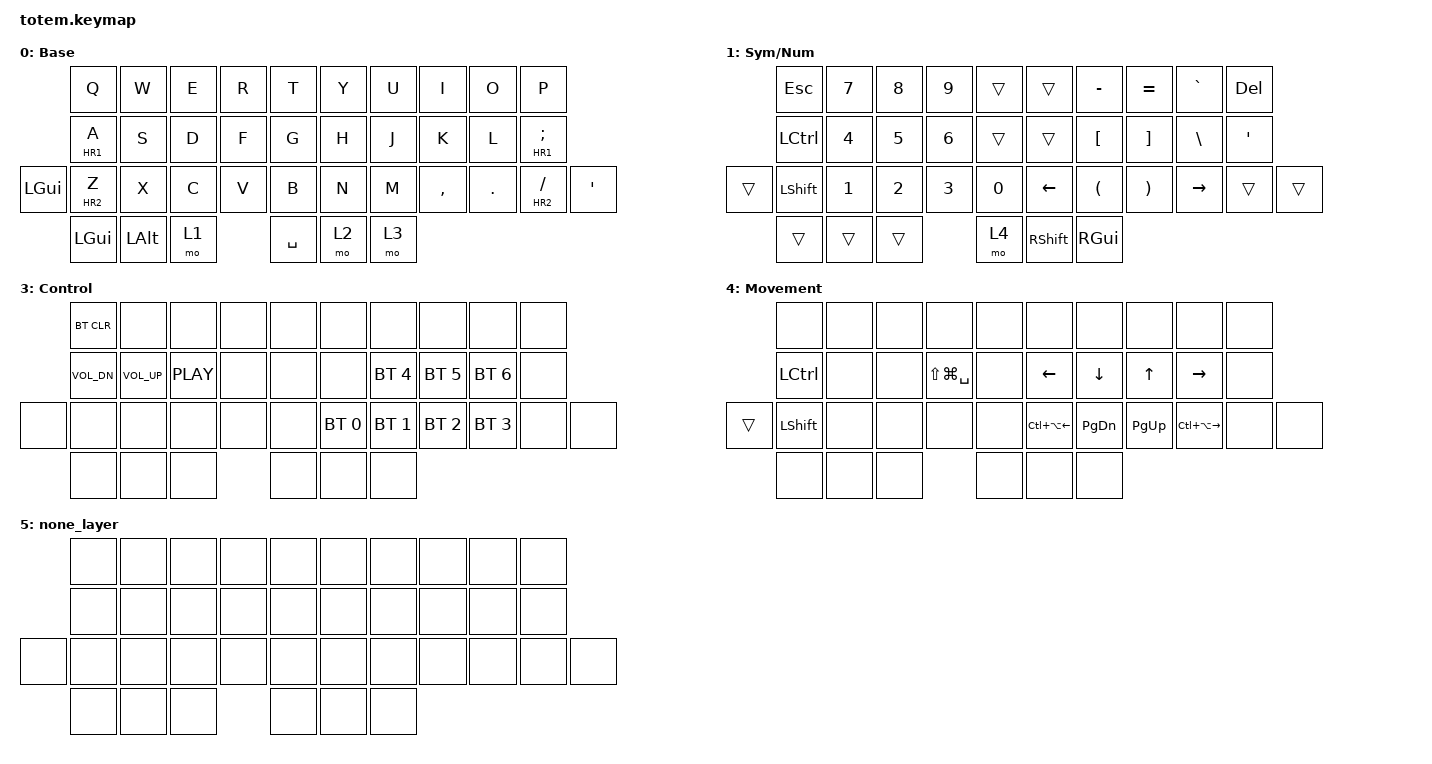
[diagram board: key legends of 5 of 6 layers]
//
//                                                        ▀▀▀▀▀     ▀▀▀▀▀          ▀▀█▀▀
//                                                        ▄▀▀▀▄  ▄  ▄▀▀▀▄  ▄  ▄▀▀▀▄  █  ▄▀▀▀▄
//                                                        █   █  █  █   █  █  █   █  █  █   █
//                                                         ▀▀▀   █   ▀▀▀   █   ▀▀▀   ▀   ▀▀▀
//                                                               █      ▄▄▄█▄▄▄    █   █  
//                                                               ▀      █  █  █     █▄█
//                                                             ▀▀▀▀▀    █  █  █      ▀
//                                                                      ▀  ▀  ▀
//
// ▄▄▄▄▄▄▄▄▄▄▄▄▄▄▄▄▄▄▄▄▄▄▄▄▄▄▄▄▄▄▄▄▄▄▄▄▄▄▄▄▄▄▄▄▄▄▄▄▄▄▄▄▄▄▄▄▄▄▄▄▄▄▄▄▄▄▄▄▄▄▄▄▄▄▄▄▄▄▄▄▄▄▄▄▄▄▄▄▄▄▄▄▄▄▄▄▄▄▄▄▄▄▄▄▄▄▄▄▄▄▄▄▄▄▄▄▄▄▄▄▄▄▄▄▄▄▄▄▄▄▄▄▄▄▄▄▄▄▄▄▄▄▄▄▄▄▄▄▄
       

#include <behaviors.dtsi>
#include <dt-bindings/zmk/keys.h>
#include <dt-bindings/zmk/bt.h>
#include <dt-bindings/zmk/outputs.h>

#define BASE 0
#define NAV  1
#define SYM  2
#define ADJ  3
#define TVP1 4
#define TVP2 5

// home row
#define HR1 LCTRL
#define HR2 LSHFT
#define HR3 RALT
#define HR4 LCTRL

#define MV_TB_L LC(LS(PG_UP))
#define MV_TB_R LC(LS(PG_DN))
#define PREV_TAB LC(LS(TAB))
#define NEXT_TAB LC(TAB)

#define PREV_SPACE LA(P)
#define NEXT_SPACE LA(N)

&lt {
    flavor = "hold-preferred";
};

&mt {
  flavor = "tap-preferred";
};

/ {
    combos {
        compatible = "zmk,combos";
        combo_esc {
            timeout-ms = <30>;
            key-positions = <1 2>;
            bindings = <&kp ESC>;
        };
        combo_tab {
            timeout-ms = <30>;
            key-positions = <11 12>;
            bindings = <&kp TAB>;
        };
        combo_bksp {
            timeout-ms = <30>;
            key-positions = <7 8>;
            bindings = <&kp BKSP>;
        };
        combo_enter {
            timeout-ms = <30>;
            key-positions = <17 18>;
            bindings = <&kp ENTER>;
        };
    };

        keymap {
                compatible = "zmk,keymap";
// ▄▄▄▄▄▄▄▄▄▄▄▄▄▄▄▄▄▄▄▄▄▄▄▄▄▄▄▄▄▄▄▄▄▄▄▄▄▄▄▄▄▄▄▄▄▄▄▄▄▄▄▄▄▄▄▄▄▄▄▄▄▄▄▄▄▄▄▄▄▄▄▄▄▄▄▄▄▄▄▄▄▄▄▄▄▄▄▄▄▄▄▄▄▄▄▄▄▄▄▄▄▄▄▄▄▄▄▄▄▄▄▄▄▄▄▄▄▄▄▄▄▄▄▄▄▄▄▄▄▄▄▄▄▄▄▄▄▄▄▄▄▄▄▄▄▄▄▄▄

                base_layer {
// ┏━━━━━━━━━━━━━━━━━━━━━━━━━━━━━━━━━━━━━━━┓
label= "Base"                              ;
// ┗━━━━━━━━━━━━━━━━━━━━━━━━━━━━━━━━━━━━━━━┛
//             ┏━━━━━━━━━━━┳━━━━━━━━━━━┳━━━━━━━━━━━┳━━━━━━━━━━━┳━━━━━━━━━━━┓   ┏━━━━━━━━━━━┳━━━━━━━━━━━┳━━━━━━━━━━━┳━━━━━━━━━━━┳━━━━━━━━━━━┓
//             ┃     Q     ┃     W     ┃     F     ┃     P     ┃     G     ┃   ┃     J     ┃     L     ┃     U     ┃     Y     ┃     ;     ┃
//             ┣━━━━━━━━━━━╋━━━━━━━━━━━╋━━━━━━━━━━━╋━━━━━━━━━━━╋━━━━━━━━━━━┫   ┣━━━━━━━━━━━╋━━━━━━━━━━━╋━━━━━━━━━━━╋━━━━━━━━━━━╋━━━━━━━━━━━┫
//             ┃     A     ┃     R     ┃     S     ┃     T     ┃     D     ┃   ┃     H     ┃     N     ┃     E     ┃     I     ┃     O     ┃
// ┏━━━━━━━━━━━╋━━━━━━━━━━━╋━━━━━━━━━━━╋━━━━━━━━━━━╋━━━━━━━━━━━╋━━━━━━━━━━━┫   ┣━━━━━━━━━━━╋━━━━━━━━━━━╋━━━━━━━━━━━╋━━━━━━━━━━━╋━━━━━━━━━━━╋━━━━━━━━━━━┓
// ┃     Q     ┃     Z     ┃     X     ┃     C     ┃     V     ┃     B     ┃   ┃     K     ┃     M     ┃     ,     ┃     .     ┃     /     ┃     \     ┃
// ┗━━━━━━━━━━━┻━━━━━━━━━━━┻━━━━━━━━━━━╋━━━━━━━━━━━╋━━━━━━━━━━━╋━━━━━━━━━━━┫   ┣━━━━━━━━━━━╋━━━━━━━━━━━╋━━━━━━━━━━━╋━━━━━━━━━━━┻━━━━━━━━━━━┻━━━━━━━━━━━┛
//                                     ┃    DEL    ┃    TAB    ┃    SPC    ┃   ┃   ENTER   ┃           ┃   BSPC    ┃
//                                     ┗━━━━━━━━━━━┻━━━━━━━━━━━┻━━━━━━━━━━━┛   ┗━━━━━━━━━━━┻━━━━━━━━━━━┻━━━━━━━━━━━┛
        bindings = <
            &kp Q &kp      W &kp      E &kp      R &kp T          &kp Y &kp      U &kp      I &kp      O &kp P
            &mt HR1 A &kp  S &kp      D &kp      F &kp G          &kp H &kp      J &kp      K &kp      L &mt HR1 SEMI 
&kp LGUI    &mt HR2 Z &kp  X &kp      C &kp      V &kp B          &kp N &kp      M &kp  COMMA &kp    DOT &mt HR2 FSLH &kp SQT
                 &kp LGUI  &kp LALT   &mo 1           &kp SPACE  &mo 2   &mo 3 
            >;
                };

// ▄▄▄▄▄▄▄▄▄▄▄▄▄▄▄▄▄▄▄▄▄▄▄▄▄▄▄▄▄▄▄▄▄▄▄▄▄▄▄▄▄▄▄▄▄▄▄▄▄▄▄▄▄▄▄▄▄▄▄▄▄▄▄▄▄▄▄▄▄▄▄▄▄▄▄▄▄▄▄▄▄▄▄▄▄▄▄▄▄▄▄▄▄▄▄▄▄▄▄▄▄▄▄▄▄▄▄▄▄▄▄▄▄▄▄▄▄▄▄▄▄▄▄▄▄▄▄▄▄▄▄▄▄▄▄▄▄▄▄▄▄▄▄▄▄▄▄▄▄


                lower_layer {
// ┏━━━━━━━━━━━━━━━━━━━━━━━━━━━━━━━━━━━━━━━┓
label= "Sym/Num"                              ;
// ┗━━━━━━━━━━━━━━━━━━━━━━━━━━━━━━━━━━━━━━━┛
//             ┏━━━━━━━━━━━┳━━━━━━━━━━━┳━━━━━━━━━━━┳━━━━━━━━━━━┳━━━━━━━━━━━┓   ┏━━━━━━━━━━━┳━━━━━━━━━━━┳━━━━━━━━━━━┳━━━━━━━━━━━┳━━━━━━━━━━━┓
//             ┃           ┃           ┃     UP    ┃           ┃     {     ┃   ┃     }     ┃     7     ┃     8     ┃     9     ┃     +     ┃
//             ┣━━━━━━━━━━━╋━━━━━━━━━━━╋━━━━━━━━━━━╋━━━━━━━━━━━╋━━━━━━━━━━━┫   ┣━━━━━━━━━━━╋━━━━━━━━━━━╋━━━━━━━━━━━╋━━━━━━━━━━━╋━━━━━━━━━━━┫
//             ┃   SHIFT   ┃   LEFT    ┃    DOWN   ┃   RIGHT   ┃     [     ┃   ┃     ]     ┃     4     ┃     5     ┃     6     ┃     -     ┃
// ┏━━━━━━━━━━━╋━━━━━━━━━━━╋━━━━━━━━━━━╋━━━━━━━━━━━╋━━━━━━━━━━━╋━━━━━━━━━━━┫   ┣━━━━━━━━━━━╋━━━━━━━━━━━╋━━━━━━━━━━━╋━━━━━━━━━━━╋━━━━━━━━━━━╋━━━━━━━━━━━┓
// ┃           ┃           ┃   P UP    ┃  C LOCK   ┃  P DOWN   ┃     (     ┃   ┃     )     ┃     1     ┃     2     ┃     3     ┃     *     ┃           ┃
// ┗━━━━━━━━━━━┻━━━━━━━━━━━┻━━━━━━━━━━━╋━━━━━━━━━━━╋━━━━━━━━━━━╋━━━━━━━━━━━┫   ┣━━━━━━━━━━━╋━━━━━━━━━━━╋━━━━━━━━━━━╋━━━━━━━━━━━┻━━━━━━━━━━━┻━━━━━━━━━━━┛
//                                     ┃           ┃    TAB    ┃    SPC    ┃   ┃    DEL    ┃     0     ┃           ┃
//                                     ┗━━━━━━━━━━━┻━━━━━━━━━━━┻━━━━━━━━━━━┛   ┗━━━━━━━━━━━┻━━━━━━━━━━━┻━━━━━━━━━━━┛
        bindings = <
                &kp ESC   &kp N7 &kp N8 &kp N9 &trans   &trans &kp MINUS &kp EQUAL  &kp GRAVE  &kp DEL
                &kp LCTRL &kp N4 &kp N5 &kp N6 &trans   &trans &kp LBKT  &kp RBKT   &kp BSLH   &kp SQT
     &trans     &kp LSHFT &kp N1 &kp N2 &kp N3 &kp N0   &kp LEFT &kp LPAR  &kp RPAR   &kp RIGHT     &trans &trans
                &trans &trans &trans   &mo 4 &kp RSHFT &kp RGUI
                >;
                };

// ▄▄▄▄▄▄▄▄▄▄▄▄▄▄▄▄▄▄▄▄▄▄▄▄▄▄▄▄▄▄▄▄▄▄▄▄▄▄▄▄▄▄▄▄▄▄▄▄▄▄▄▄▄▄▄▄▄▄▄▄▄▄▄▄▄▄▄▄▄▄▄▄▄▄▄▄▄▄▄▄▄▄▄▄▄▄▄▄▄▄▄▄▄▄▄▄▄▄▄▄▄▄▄▄▄▄▄▄▄▄▄▄▄▄▄▄▄▄▄▄▄▄▄▄▄▄▄▄▄▄▄▄▄▄▄▄▄▄▄▄▄▄▄▄▄▄▄▄▄


                nav_layer {
// ┏━━━━━━━━━━━━━━━━━━━━━━━━━━━━━━━━━━━━━━━┓
label= "Nav"                               ;
// ┗━━━━━━━━━━━━━━━━━━━━━━━━━━━━━━━━━━━━━━━┛
//             ┏━━━━━━━━━━━┳━━━━━━━━━━━┳━━━━━━━━━━━┳━━━━━━━━━━━┳━━━━━━━━━━━┓   ┏━━━━━━━━━━━┳━━━━━━━━━━━┳━━━━━━━━━━━┳━━━━━━━━━━━┳━━━━━━━━━━━┓
//             ┃     !     ┃     @     ┃     #     ┃     $     ┃     %     ┃   ┃     ˆ     ┃     &     ┃     Ü     ┃     '     ┃     "     ┃
//             ┣━━━━━━━━━━━╋━━━━━━━━━━━╋━━━━━━━━━━━╋━━━━━━━━━━━╋━━━━━━━━━━━┫   ┣━━━━━━━━━━━╋━━━━━━━━━━━╋━━━━━━━━━━━╋━━━━━━━━━━━╋━━━━━━━━━━━┫
//             ┃     Ä     ┃           ┃    SZ     ┃           ┃           ┃   ┃   MUTE    ┃   YEN     ┃   EURO    ┃  POUND    ┃     Ö     ┃
// ┏━━━━━━━━━━━╋━━━━━━━━━━━╋━━━━━━━━━━━╋━━━━━━━━━━━╋━━━━━━━━━━━╋━━━━━━━━━━━┫   ┣━━━━━━━━━━━╋━━━━━━━━━━━╋━━━━━━━━━━━╋━━━━━━━━━━━╋━━━━━━━━━━━╋━━━━━━━━━━━┓
// ┃           ┃  EMAIL1   ┃  EMAIL2   ┃           ┃           ┃           ┃   ┃   VOL-    ┃   VOL+    ┃   LAST    ┃   NEXT    ┃     \     ┃           ┃
// ┗━━━━━━━━━━━┻━━━━━━━━━━━┻━━━━━━━━━━━╋━━━━━━━━━━━╋━━━━━━━━━━━╋━━━━━━━━━━━┫   ┣━━━━━━━━━━━╋━━━━━━━━━━━╋━━━━━━━━━━━╋━━━━━━━━━━━┻━━━━━━━━━━━┻━━━━━━━━━━━┛
//                                     ┃           ┃    GIF    ┃    ADJ    ┃   ┃           ┃           ┃           ┃
//                                     ┗━━━━━━━━━━━┻━━━━━━━━━━━┻━━━━━━━━━━━┛   ┗━━━━━━━━━━━┻━━━━━━━━━━━┻━━━━━━━━━━━┛
        bindings = <
                &kp LG(N1)    &kp LG(N2)   &kp LG(N3) &kp LG(N4)   &kp LG(N5)         &kp LG(N6)    &kp LG(N7)   &kp LG(N8) &kp LG(N9)  &trans 
                &kp LCTRL     &kp LA(N4)   &kp LA(N5) &kp LA(N6)   &trans             &kp MV_TB_L &kp PREV_TAB &kp NEXT_TAB &kp MV_TB_R &kp BSLH
       &trans   &kp LSHFT     &kp LA(N1)   &kp LA(N2) &kp LA(N3)   &trans             &kp LS(LA(P)) &kp LA(P)  &kp LA(N) &kp LS(LA(N))  &trans
                &trans &trans &trans   &trans &trans &trans
                >;
        };

// ▄▄▄▄▄▄▄▄▄▄▄▄▄▄▄▄▄▄▄▄▄▄▄▄▄▄▄▄▄▄▄▄▄▄▄▄▄▄▄▄▄▄▄▄▄▄▄▄▄▄▄▄▄▄▄▄▄▄▄▄▄▄▄▄▄▄▄▄▄▄▄▄▄▄▄▄▄▄▄▄▄▄▄▄▄▄▄▄▄▄▄▄▄▄▄▄▄▄▄▄▄▄▄▄▄▄▄▄▄▄▄▄▄▄▄▄▄▄▄▄▄▄▄▄▄▄▄▄▄▄▄▄▄▄▄▄▄▄▄▄▄▄▄▄▄▄▄▄▄


                control_layer {
// ┏━━━━━━━━━━━━━━━━━━━━━━━━━━━━━━━━━━━━━━━┓
label= "Control"                               ;
// ┗━━━━━━━━━━━━━━━━━━━━━━━━━━━━━━━━━━━━━━━┛
//             ┏━━━━━━━━━━━┳━━━━━━━━━━━┳━━━━━━━━━━━┳━━━━━━━━━━━┳━━━━━━━━━━━┓   ┏━━━━━━━━━━━┳━━━━━━━━━━━┳━━━━━━━━━━━┳━━━━━━━━━━━┳━━━━━━━━━━━┓
//             ┃   RESET   ┃ BT CLEAR  ┃  OUT TOG  ┃           ┃           ┃   ┃           ┃    F7     ┃    F8     ┃    F9     ┃    F12    ┃
//             ┣━━━━━━━━━━━╋━━━━━━━━━━━╋━━━━━━━━━━━╋━━━━━━━━━━━╋━━━━━━━━━━━┫   ┣━━━━━━━━━━━╋━━━━━━━━━━━╋━━━━━━━━━━━╋━━━━━━━━━━━╋━━━━━━━━━━━┫
//             ┃ BOOTLOAD  ┃ BT NEXT   ┃           ┃           ┃           ┃   ┃           ┃    F4     ┃    F5     ┃    F6     ┃    F11    ┃
// ┏━━━━━━━━━━━╋━━━━━━━━━━━╋━━━━━━━━━━━╋━━━━━━━━━━━╋━━━━━━━━━━━╋━━━━━━━━━━━┫   ┣━━━━━━━━━━━╋━━━━━━━━━━━╋━━━━━━━━━━━╋━━━━━━━━━━━╋━━━━━━━━━━━╋━━━━━━━━━━━┓
// ┃           ┃           ┃ BT PREV   ┃           ┃           ┃           ┃   ┃           ┃    F1     ┃    F2     ┃    F3     ┃    F10    ┃           ┃
// ┗━━━━━━━━━━━┻━━━━━━━━━━━┻━━━━━━━━━━━╋━━━━━━━━━━━╋━━━━━━━━━━━╋━━━━━━━━━━━┫   ┣━━━━━━━━━━━╋━━━━━━━━━━━╋━━━━━━━━━━━╋━━━━━━━━━━━┻━━━━━━━━━━━┻━━━━━━━━━━━┛
//                                     ┃           ┃           ┃           ┃   ┃           ┃           ┃           ┃
//                                     ┗━━━━━━━━━━━┻━━━━━━━━━━━┻━━━━━━━━━━━┛   ┗━━━━━━━━━━━┻━━━━━━━━━━━┻━━━━━━━━━━━┛
            bindings = <
&bt BT_CLR   &none        &none      &none &none    &none &none &none &none &none
&kp C_VOL_DN &kp C_VOL_UP &kp C_PLAY &none &none    &none &bt BT_SEL 4 &bt BT_SEL 5 &bt BT_SEL 6 &none
&none &none &none &none &none &none                       &bt BT_SEL 0 &bt BT_SEL 1 &bt BT_SEL 2 &bt BT_SEL 3 &none &none
            &none &none &none                       &none &none &none
            >;
                };

// ▄▄▄▄▄▄▄▄▄▄▄▄▄▄▄▄▄▄▄▄▄▄▄▄▄▄▄▄▄▄▄▄▄▄▄▄▄▄▄▄▄▄▄▄▄▄▄▄▄▄▄▄▄▄▄▄▄▄▄▄▄▄▄▄▄▄▄▄▄▄▄▄▄▄▄▄▄▄▄▄▄▄▄▄▄▄▄▄▄▄▄▄▄▄▄▄▄▄▄▄▄▄▄▄▄▄▄▄▄▄▄▄▄▄▄▄▄▄▄▄▄▄▄▄▄▄▄▄▄▄▄▄▄▄▄▄▄▄▄▄▄▄▄▄▄▄▄▄▄


                movement_layer {
// ┏━━━━━━━━━━━━━━━━━━━━━━━━━━━━━━━━━━━━━━━┓
label= "Movement"                             ;
// ┗━━━━━━━━━━━━━━━━━━━━━━━━━━━━━━━━━━━━━━━┛
//             ┏━━━━━━━━━━━┳━━━━━━━━━━━┳━━━━━━━━━━━┳━━━━━━━━━━━┳━━━━━━━━━━━┓   ┏━━━━━━━━━━━┳━━━━━━━━━━━┳━━━━━━━━━━━┳━━━━━━━━━━━┳━━━━━━━━━━━┓
//             ┃ NEXT FILE ┃ MARK IN   ┃ ROTATE    ┃ MARK OUT  ┃ SHOW SNAP ┃   ┃           ┃           ┃           ┃           ┃           ┃
//             ┣━━━━━━━━━━━╋━━━━━━━━━━━╋━━━━━━━━━━━╋━━━━━━━━━━━╋━━━━━━━━━━━┫   ┣━━━━━━━━━━━╋━━━━━━━━━━━╋━━━━━━━━━━━╋━━━━━━━━━━━╋━━━━━━━━━━━┫
//             ┃ TVP II    ┃ LEFT      ┃ PAN       ┃ RIGHT     ┃ PLAY/FLIP ┃   ┃           ┃           ┃           ┃           ┃           ┃
// ┏━━━━━━━━━━━╋━━━━━━━━━━━╋━━━━━━━━━━━╋━━━━━━━━━━━╋━━━━━━━━━━━╋━━━━━━━━━━━┫   ┣━━━━━━━━━━━╋━━━━━━━━━━━╋━━━━━━━━━━━╋━━━━━━━━━━━╋━━━━━━━━━━━╋━━━━━━━━━━━┓
// ┃ FULLSCR   ┃ SHIFT     ┃ COPY      ┃ DELETE    ┃ PASTE     ┃ IMG MARK  ┃   ┃           ┃           ┃           ┃           ┃           ┃           ┃
// ┗━━━━━━━━━━━┻━━━━━━━━━━━┻━━━━━━━━━━━╋━━━━━━━━━━━╋━━━━━━━━━━━╋━━━━━━━━━━━┫   ┣━━━━━━━━━━━╋━━━━━━━━━━━╋━━━━━━━━━━━╋━━━━━━━━━━━┻━━━━━━━━━━━┻━━━━━━━━━━━┛
//                                     ┃           ┃ UNDO/SAVE ┃  SEL/MOV  ┃   ┃           ┃           ┃           ┃
//                                     ┗━━━━━━━━━━━┻━━━━━━━━━━━┻━━━━━━━━━━━┛   ┗━━━━━━━━━━━┻━━━━━━━━━━━┻━━━━━━━━━━━┛
            bindings = <
        &none &none &none &none &none    &none &none &none &none &none
        &kp LCTRL &none &none &kp LS(LG(SPACE)) &none    &kp LEFT &kp DOWN &kp UP &kp RIGHT &none
&trans &kp LSHFT &none &none &none &none    &kp LC(LA(LEFT)) &kp PG_DN &kp PG_UP &kp LC(LA(RIGHT)) &none &none
            &none &none &none    &none &none &none
            >;
                };

// ▄▄▄▄▄▄▄▄▄▄▄▄▄▄▄▄▄▄▄▄▄▄▄▄▄▄▄▄▄▄▄▄▄▄▄▄▄▄▄▄▄▄▄▄▄▄▄▄▄▄▄▄▄▄▄▄▄▄▄▄▄▄▄▄▄▄▄▄▄▄▄▄▄▄▄▄▄▄▄▄▄▄▄▄▄▄▄▄▄▄▄▄▄▄▄▄▄▄▄▄▄▄▄▄▄▄▄▄▄▄▄▄▄▄▄▄▄▄▄▄▄▄▄▄▄▄▄▄▄▄▄▄▄▄▄▄▄▄▄▄▄▄▄▄▄▄▄▄▄


        none_layer {
            bindings = <
&none &none &none &none &none    &none &none &none &none &none
&none &none &none &none &none    &none &none &none &none &none
&none &none &none &none &none &none    &none &none &none &none &none &none
            &none &none &none    &none &none &none
            >;
        };

        };
};
